# ATmega3209 register map
Vendor: Atmel; File version: 1.0
CPU: other r0p0, little endian, no MPU, no FPU, 4 interrupt priority bits
Registers are 8-bit, read-write, reset 0x0 unless marked. A register's access mark holds for its fields unless they carry their own. Offsets are from the block's base; [hi:lo] are bit positions; {n}, {i} and the like mark numbered series; 'fields as' and 'values as' point back to an identical list.

## CPU
Base 0x00000034
0x00 CCP — Configuration Change Protection
  [7:0] CCP — CCP signature
    157=SPM (SPM Instruction Protection); 216=IOREG (IO Register Protection)
0x09 SPL — Stack Pointer Low
0x0A SPH — Stack Pointer High

## CPUINT — Interrupt Controller
Base 0x00000110
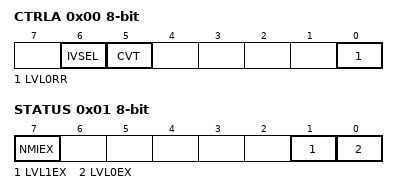
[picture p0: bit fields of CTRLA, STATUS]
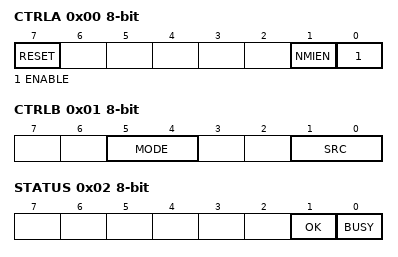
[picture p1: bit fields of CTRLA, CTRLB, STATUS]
0x00 CTRLA — Control A
  [6] IVSEL — Interrupt Vector Select
  [5] CVT — Compact Vector Table
  [0] LVL0RR — Round-robin Scheduling Enable
0x01 STATUS
  [7] NMIEX ro — Non-maskable Interrupt Executing
  [1] LVL1EX ro — Level 1 Interrupt Executing
  [0] LVL0EX ro — Level 0 Interrupt Executing
0x02 LVL0PRI — Interrupt Level 0 Priority
  [7:0] LVL0PRI — Interrupt Level Priority
0x03 LVL1VEC — Interrupt Level 1 Priority Vector
  [7:0] LVL1VEC — Interrupt Vector with High Priority

## CRCSCAN
Base 0x00000120
0x00 CTRLA — Control A
  [7] RESET — Reset CRC scan
  [1] NMIEN — Enable NMI Trigger
  [0] ENABLE — Enable CRC scan
0x01 CTRLB — Control B
  [5:4] MODE — CRC Flash Access Mode
    0=PRIORITY (Priority to flash); 2=BACKGROUND (Lowest priority to flash); 3=CONTINUOUS (Continuous checks in background)
  [1:0] SRC — CRC Source
    0=FLASH (CRC on entire flash); 1=APPLICATION (CRC on boot and appl section of flash); 2=BOOT (CRC on boot section of flash)
0x02 STATUS ro
  [1] OK — CRC Ok
  [0] BUSY — CRC Busy

## EVSYS — Event System
Base 0x00000180
0x00 STROBE wo — Channel Strobe
  [7:0] STROBE0 — Software event on channels
    1=EV_STROBE_CH0; 2=EV_STROBE_CH1; 4=EV_STROBE_CH2; 8=EV_STROBE_CH3; 16=EV_STROBE_CH4; 32=EV_STROBE_CH5; 64=EV_STROBE_CH6; 128=EV_STROBE_CH7
{0x10+i} CHANNEL{i} (i=0..7) — Multiplexer Channel {i}
  [7:0] GENERATOR — Generator selector
    0=OFF; 1=UPDI (Unified Program and Debug Interface); 6=RTC_OVF (Real Time Counter overflow); 7=RTC_CMP (Real Time Counter compare); {v}=RTC_PIT{v-8} (Periodic Interrupt Timer output {v-8}) (v=8..11); {v}=CCL_LUT{v-16} (Configurable Custom Logic LUT{v-16}) (v=16..19); 32=AC0_OUT (Analog Comparator 0 out); 36=ADC0_COMP (ADC 0 Comparator Event); {v}=PORT0_PIN{v-64} (v=64..71); {v}=PORT1_PIN{v-72} (v=72..79); {v}=USART{v-96}_XCK (USART {v-96} Xclock) (v=96..99); 104=SPI0_SCK (SPI 0 Sclock); 128=TCA0_OVF_LUNF (Timer/Counter A0 overflow / low byte underflow); 129=TCA0_HUNF (Timer/Counter A0 high byte underflow (split mode)); 132=TCA0_CMP0 (Timer/Counter A0 compare 0); 133=TCA0_CMP1 (Timer/Counter A0 compare 1); 134=TCA0_CMP2 (Timer/Counter A0 compare 2); 160=TCB0_CMP0 (Timer/Counter B0 compare 0); 162=TCB1_CMP0 (Timer/Counter B1 compare 0); 164=TCB2_CMP0 (Timer/Counter B2 compare 0); 166=TCB3_CMP0 (Timer/Counter B3 compare 0)
{0x20+2i} USERCCLLUT{i}A (i=0..3) — User CCL LUT{i} Event A
  [7:0] CHANNEL — Channel selector
    0=OFF; {v}=Connect user to event channel {v-1} (v=1..8)
{0x21+2i} USERCCLLUT{i}B (i=0..3) — User CCL LUT{i} Event B
  fields as USERCCLLUT0A
0x28 USERADC0
  fields as USERCCLLUT0A
0x29 USEREVOUTA — User EVOUT Port A
  fields as USERCCLLUT0A
0x2A USEREVOUTB — User EVOUT Port B
  fields as USERCCLLUT0A
0x2B USEREVOUTC — User EVOUT Port C
  fields as USERCCLLUT0A
0x2C USEREVOUTD — User EVOUT Port D
  fields as USERCCLLUT0A
0x2D USEREVOUTE — User EVOUT Port E
  fields as USERCCLLUT0A
0x2E USEREVOUTF — User EVOUT Port F
  fields as USERCCLLUT0A
{0x2F+i} USERUSART{i} (i=0..3)
  fields as USERCCLLUT0A
0x33 USERTCA0
  fields as USERCCLLUT0A
{0x34+i} USERTCB{i} (i=0..3)
  fields as USERCCLLUT0A

## FUSE — Fuses
Base 0x00001280
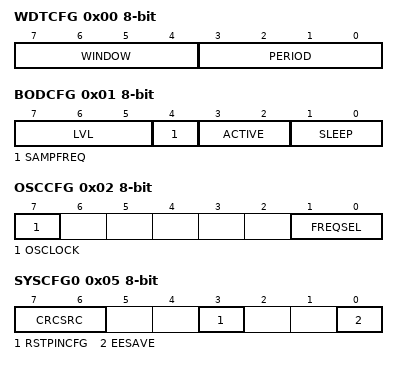
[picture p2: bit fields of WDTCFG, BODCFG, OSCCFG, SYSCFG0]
0x00 WDTCFG — Watchdog Configuration
  [7:4] WINDOW — Watchdog Window Timeout Period
    0=OFF; 1=8CLK (8 cycles (8ms)); 2=16CLK (16 cycles (16ms)); 3=32CLK (32 cycles (32ms)); 4=64CLK (64 cycles (64ms)); 5=128CLK (128 cycles (0.128s)); 6=256CLK (256 cycles (0.256s)); 7=512CLK (512 cycles (0.512s)); 8=1KCLK (1K cycles (1.0s)); 9=2KCLK (2K cycles (2.0s)); 10=4KCLK (4K cycles (4.1s)); 11=8KCLK (8K cycles (8.2s))
  [3:0] PERIOD — Watchdog Timeout Period
    values as WINDOW
0x01 BODCFG — BOD Configuration
  [7:5] LVL — BOD Level
    0=BODLEVEL0 (1.8 V); 1=BODLEVEL1 (2.1 V); 2=BODLEVEL2 (2.6 V); 3=BODLEVEL3 (2.9 V); 4=BODLEVEL4 (3.3 V); 5=BODLEVEL5 (3.7 V); 6=BODLEVEL6 (4.0 V); 7=BODLEVEL7 (4.2 V)
  [4] SAMPFREQ — BOD Sample Frequency
    0=1KHZ (1kHz sampling frequency); 1=125HZ (125Hz sampling frequency)
  [3:2] ACTIVE — BOD Operation in Active Mode
    0=DIS (Disabled); 1=ENABLED; 2=SAMPLED; 3=ENWAKE (Enabled with wake-up halted until BOD is ready)
  [1:0] SLEEP — BOD Operation in Sleep Mode
    0=DIS (Disabled); 1=ENABLED; 2=SAMPLED
0x02 OSCCFG — Oscillator Configuration
  [7] OSCLOCK — Oscillator Lock
  [1:0] FREQSEL — Frequency Select
    1=16MHZ; 2=20MHZ
0x05 SYSCFG0 — System Configuration 0
  [7:6] CRCSRC — CRC Source
    0=FLASH (The CRC is performed on the entire Flash (boot, application code and application data section).); 1=BOOT (The CRC is performed on the boot section of Flash); 2=BOOTAPP (The CRC is performed on the boot and application code section of Flash); 3=NOCRC (Disable CRC.)
  [3] RSTPINCFG — Reset Pin Configuration
    0=GPIO (GPIO mode); 1=RST (Reset mode)
  [0] EESAVE — EEPROM Save
0x06 SYSCFG1 — System Configuration 1
  [2:0] SUT — Startup Time
    0=0MS; 1=1MS; 2=2MS; 3=4MS; 4=8MS; 5=16MS; 6=32MS; 7=64MS
0x07 APPEND — Application Code Section End
0x08 BOOTEND — Boot Section End
